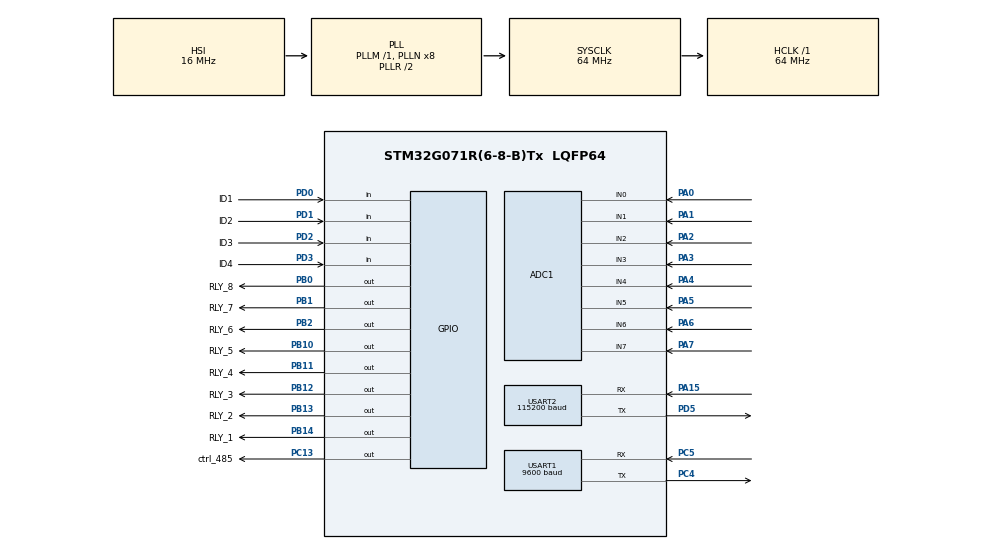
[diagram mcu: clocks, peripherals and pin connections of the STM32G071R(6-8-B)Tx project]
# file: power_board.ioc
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ADC1.Channel-0\#ChannelRegularConversion=ADC_CHANNEL_0
ADC1.Channel-1\#ChannelRegularConversion=ADC_CHANNEL_1
ADC1.Channel-2\#ChannelRegularConversion=ADC_CHANNEL_2
ADC1.Channel-3\#ChannelRegularConversion=ADC_CHANNEL_3
ADC1.Channel-4\#ChannelRegularConversion=ADC_CHANNEL_4
ADC1.Channel-5\#ChannelRegularConversion=ADC_CHANNEL_5
ADC1.Channel-6\#ChannelRegularConversion=ADC_CHANNEL_6
ADC1.Channel-7\#ChannelRegularConversion=ADC_CHANNEL_7
ADC1.ContinuousConvMode=ENABLE
ADC1.DMAContinuousRequests=ENABLE
ADC1.NbrOfConversion=8
ADC1.NbrOfConversionFlag=1
ADC1.Rank-0\#ChannelRegularConversion=1
ADC1.Rank-1\#ChannelRegularConversion=2
ADC1.Rank-2\#ChannelRegularConversion=3
ADC1.Rank-3\#ChannelRegularConversion=4
ADC1.Rank-4\#ChannelRegularConversion=5
ADC1.Rank-5\#ChannelRegularConversion=6
ADC1.Rank-6\#ChannelRegularConversion=7
ADC1.Rank-7\#ChannelRegularConversion=8
ADC1.SamplingTime-0\#ChannelRegularConversion=ADC_SAMPLINGTIME_COMMON_1
ADC1.SamplingTime-1\#ChannelRegularConversion=ADC_SAMPLINGTIME_COMMON_1
ADC1.SamplingTime-2\#ChannelRegularConversion=ADC_SAMPLINGTIME_COMMON_1
ADC1.SamplingTime-3\#ChannelRegularConversion=ADC_SAMPLINGTIME_COMMON_1
ADC1.SamplingTime-4\#ChannelRegularConversion=ADC_SAMPLINGTIME_COMMON_1
ADC1.SamplingTime-5\#ChannelRegularConversion=ADC_SAMPLINGTIME_COMMON_1
ADC1.SamplingTime-6\#ChannelRegularConversion=ADC_SAMPLINGTIME_COMMON_1
ADC1.SamplingTime-7\#ChannelRegularConversion=ADC_SAMPLINGTIME_COMMON_1
ADC1.SamplingTimeCommon1=ADC_SAMPLETIME_12CYCLES_5
ADC1.SamplingTimeCommon2=ADC_SAMPLETIME_12CYCLES_5
ADC1.SelectedChannel=ADC_CHANNEL_0|ADC_CHANNEL_1|ADC_CHANNEL_2|ADC_CHANNEL_3|ADC_CHANNEL_4|ADC_CHANNEL_5|ADC_CHANNEL_6|ADC_CHANNEL_7
ADC1.master=1
Dma.ADC1.0.Direction=DMA_PERIPH_TO_MEMORY
Dma.ADC1.0.EventEnable=DISABLE
Dma.ADC1.0.Instance=DMA1_Channel1
Dma.ADC1.0.MemDataAlignment=DMA_MDATAALIGN_HALFWORD
Dma.ADC1.0.MemInc=DMA_MINC_ENABLE
Dma.ADC1.0.Mode=DMA_CIRCULAR
Dma.ADC1.0.PeriphDataAlignment=DMA_PDATAALIGN_HALFWORD
Dma.ADC1.0.PeriphInc=DMA_PINC_DISABLE
Dma.ADC1.0.Polarity=HAL_DMAMUX_REQ_GEN_RISING
Dma.ADC1.0.Priority=DMA_PRIORITY_LOW
Dma.ADC1.0.RequestNumber=1
Dma.ADC1.0.SignalID=NONE
Dma.ADC1.0.SyncEnable=DISABLE
Dma.ADC1.0.SyncPolarity=HAL_DMAMUX_SYNC_NO_EVENT
Dma.ADC1.0.SyncRequestNumber=1
Dma.ADC1.0.SyncSignalID=NONE
Dma.Request0=ADC1
Mcu.Family=STM32G0
Mcu.Name=STM32G071R(6-8-B)Tx
Mcu.Package=LQFP64
NVIC.DMA1_Channel1_IRQn=true\:0\:0\:false\:false\:true\:false\:true\:true
NVIC.USART1_IRQn=true\:0\:0\:false\:false\:true\:true\:true\:true
PA0.Mode=IN0
PA0.Signal=ADC1_IN0
PA1.Mode=IN1
PA1.Signal=ADC1_IN1
PA13.Mode=Serial_Wire
PA13.Signal=SYS_SWDIO
PA14-BOOT0.Mode=Serial_Wire
PA14-BOOT0.Signal=SYS_SWCLK
PA15.Mode=Asynchronous
PA15.Signal=USART2_RX
PA2.Mode=IN2
PA2.Signal=ADC1_IN2
PA3.Mode=IN3
PA3.Signal=ADC1_IN3
PA4.Mode=IN4
PA4.Signal=ADC1_IN4
PA5.Mode=IN5
PA5.Signal=ADC1_IN5
PA6.Mode=IN6
PA6.Signal=ADC1_IN6
PA7.Mode=IN7
PA7.Signal=ADC1_IN7
PB0.GPIO_Label=RLY_8
PB0.Signal=GPIO_Output
PB1.GPIO_Label=RLY_7
PB1.Signal=GPIO_Output
PB10.GPIO_Label=RLY_5
PB10.Signal=GPIO_Output
PB11.GPIO_Label=RLY_4
PB11.Signal=GPIO_Output
PB12.GPIO_Label=RLY_3
PB12.Signal=GPIO_Output
PB13.GPIO_Label=RLY_2
PB13.Signal=GPIO_Output
PB14.GPIO_Label=RLY_1
PB14.Signal=GPIO_Output
PB2.GPIO_Label=RLY_6
PB2.Signal=GPIO_Output
PC13.GPIO_Label=ctrl_485
PC13.Signal=GPIO_Output
PC4.Mode=Asynchronous
PC4.Signal=USART1_TX
PC5.Mode=Asynchronous
PC5.Signal=USART1_RX
PD0.GPIO_Label=ID1
PD0.GPIO_PuPd=GPIO_PULLUP
PD0.Signal=GPIO_Input
PD1.GPIO_Label=ID2
PD1.GPIO_PuPd=GPIO_PULLUP
PD1.Signal=GPIO_Input
PD2.GPIO_Label=ID3
PD2.GPIO_PuPd=GPIO_PULLUP
PD2.Signal=GPIO_Input
PD3.GPIO_Label=ID4
PD3.GPIO_PuPd=GPIO_PULLUP
PD3.Signal=GPIO_Input
PD5.Mode=Asynchronous
PD5.Signal=USART2_TX
ProjectManager.HeapSize=0x200
ProjectManager.StackSize=0x400
ProjectManager.TargetToolchain=STM32CubeIDE
RCC.ADCFreq_Value=64000000
RCC.AHBFreq_Value=64000000
RCC.CortexFreq_Value=64000000
RCC.EXTERNAL_CLOCK_VALUE=48000
RCC.HCLKFreq_Value=64000000
RCC.HSE_VALUE=8000000
RCC.HSI_VALUE=16000000
RCC.LSE_VALUE=32768
RCC.SYSCLKFreq_VALUE=64000000
RCC.SYSCLKSource=RCC_SYSCLKSOURCE_PLLCLK
RCC.VCOOutputFreq_Value=128000000
USART1.BaudRate=9600
USART1.VirtualMode-Asynchronous=VM_ASYNC
USART2.BaudRate=115200
USART2.VirtualMode-Asynchronous=VM_ASYNC
board=custom

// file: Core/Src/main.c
/* USER CODE BEGIN Header */
/**
  ******************************************************************************
  * @file           : main.c
  * @brief          : Main program body
  ******************************************************************************
  * @attention
  *
  * Copyright (c) 2026 STMicroelectronics.
  * All rights reserved.
  *
  * This software is licensed under terms that can be found in the LICENSE file
  * in the root directory of this software component.
  * If no LICENSE file comes with this software, it is provided AS-IS.
  *
  ******************************************************************************
  */
/* USER CODE END Header */
#include "main.h"

/* USER CODE BEGIN Includes */
#include "app.h"
#include <stdio.h>
/* USER CODE END Includes */

ADC_HandleTypeDef hadc1;
DMA_HandleTypeDef hdma_adc1;

UART_HandleTypeDef huart1;
UART_HandleTypeDef huart2;

void SystemClock_Config(void);
static void MX_GPIO_Init(void);
static void MX_DMA_Init(void);
static void MX_ADC1_Init(void);
static void MX_USART1_UART_Init(void);
static void MX_USART2_UART_Init(void);

int main(void)
{

  /* MCU Configuration--------------------------------------------------------*/

  /* Reset of all peripherals, Initializes the Flash interface and the Systick. */
  HAL_Init();

  /* Configure the system clock */
  SystemClock_Config();

  /* Initialize all configured peripherals */
  MX_GPIO_Init();
  MX_DMA_Init();
  MX_ADC1_Init();
  MX_USART1_UART_Init();
  MX_USART2_UART_Init();

  /* Infinite loop */
  /* USER CODE BEGIN WHILE */
  App_Init();
  while (1)
  {

	  App_Run();
    /* USER CODE END WHILE */

  }
}

void SystemClock_Config(void)
{
  RCC_OscInitTypeDef RCC_OscInitStruct = {0};
  RCC_ClkInitTypeDef RCC_ClkInitStruct = {0};

  /** Configure the main internal regulator output voltage
  */
  HAL_PWREx_ControlVoltageScaling(PWR_REGULATOR_VOLTAGE_SCALE1);

  /** Initializes the RCC Oscillators according to the specified parameters
  * in the RCC_OscInitTypeDef structure.
  */
  RCC_OscInitStruct.OscillatorType = RCC_OSCILLATORTYPE_HSI;
  RCC_OscInitStruct.HSIState = RCC_HSI_ON;
  RCC_OscInitStruct.HSIDiv = RCC_HSI_DIV1;
  RCC_OscInitStruct.HSICalibrationValue = RCC_HSICALIBRATION_DEFAULT;
  RCC_OscInitStruct.PLL.PLLState = RCC_PLL_ON;
  RCC_OscInitStruct.PLL.PLLSource = RCC_PLLSOURCE_HSI;
  RCC_OscInitStruct.PLL.PLLM = RCC_PLLM_DIV1;
  RCC_OscInitStruct.PLL.PLLN = 8;
  RCC_OscInitStruct.PLL.PLLP = RCC_PLLP_DIV2;
  RCC_OscInitStruct.PLL.PLLQ = RCC_PLLQ_DIV2;
  RCC_OscInitStruct.PLL.PLLR = RCC_PLLR_DIV2;
  if (HAL_RCC_OscConfig(&RCC_OscInitStruct) != HAL_OK)
  {
    Error_Handler();
  }

  /** Initializes the CPU, AHB and APB buses clocks
  */
  RCC_ClkInitStruct.ClockType = RCC_CLOCKTYPE_HCLK|RCC_CLOCKTYPE_SYSCLK
                              |RCC_CLOCKTYPE_PCLK1;
  RCC_ClkInitStruct.SYSCLKSource = RCC_SYSCLKSOURCE_PLLCLK;
  RCC_ClkInitStruct.AHBCLKDivider = RCC_SYSCLK_DIV1;
  RCC_ClkInitStruct.APB1CLKDivider = RCC_HCLK_DIV1;

  if (HAL_RCC_ClockConfig(&RCC_ClkInitStruct, FLASH_LATENCY_2) != HAL_OK)
  {
    Error_Handler();
  }
}

static void MX_ADC1_Init(void)
{

  ADC_ChannelConfTypeDef sConfig = {0};

  /** Configure the global features of the ADC (Clock, Resolution, Data Alignment and number of conversion)
  */
  hadc1.Instance = ADC1;
  hadc1.Init.ClockPrescaler = ADC_CLOCK_SYNC_PCLK_DIV2;
  hadc1.Init.Resolution = ADC_RESOLUTION_12B;
  hadc1.Init.DataAlign = ADC_DATAALIGN_RIGHT;
  hadc1.Init.ScanConvMode = ADC_SCAN_ENABLE;
  hadc1.Init.EOCSelection = ADC_EOC_SINGLE_CONV;
  hadc1.Init.LowPowerAutoWait = DISABLE;
  hadc1.Init.LowPowerAutoPowerOff = DISABLE;
  hadc1.Init.ContinuousConvMode = ENABLE;
  hadc1.Init.NbrOfConversion = 8;
  hadc1.Init.ExternalTrigConv = ADC_SOFTWARE_START;
  hadc1.Init.ExternalTrigConvEdge = ADC_EXTERNALTRIGCONVEDGE_NONE;
  hadc1.Init.DMAContinuousRequests = ENABLE;
  hadc1.Init.Overrun = ADC_OVR_DATA_PRESERVED;
  hadc1.Init.SamplingTimeCommon1 = ADC_SAMPLETIME_12CYCLES_5;
  hadc1.Init.SamplingTimeCommon2 = ADC_SAMPLETIME_12CYCLES_5;
  hadc1.Init.OversamplingMode = DISABLE;
  hadc1.Init.TriggerFrequencyMode = ADC_TRIGGER_FREQ_HIGH;
  if (HAL_ADC_Init(&hadc1) != HAL_OK)
  {
    Error_Handler();
  }

  /** Configure Regular Channel
  */
  sConfig.Channel = ADC_CHANNEL_0;
  sConfig.Rank = ADC_REGULAR_RANK_1;
  sConfig.SamplingTime = ADC_SAMPLINGTIME_COMMON_1;
  if (HAL_ADC_ConfigChannel(&hadc1, &sConfig) != HAL_OK)
  {
    Error_Handler();
  }

  /** Configure Regular Channel
  */
  sConfig.Channel = ADC_CHANNEL_1;
  sConfig.Rank = ADC_REGULAR_RANK_2;
  if (HAL_ADC_ConfigChannel(&hadc1, &sConfig) != HAL_OK)
  {
    Error_Handler();
  }

  /** Configure Regular Channel
  */
  sConfig.Channel = ADC_CHANNEL_2;
  sConfig.Rank = ADC_REGULAR_RANK_3;
  if (HAL_ADC_ConfigChannel(&hadc1, &sConfig) != HAL_OK)
  {
    Error_Handler();
  }

  /** Configure Regular Channel
  */
  sConfig.Channel = ADC_CHANNEL_3;
  sConfig.Rank = ADC_REGULAR_RANK_4;
  if (HAL_ADC_ConfigChannel(&hadc1, &sConfig) != HAL_OK)
  {
    Error_Handler();
  }

  /** Configure Regular Channel
  */
  sConfig.Channel = ADC_CHANNEL_4;
  sConfig.Rank = ADC_REGULAR_RANK_5;
  if (HAL_ADC_ConfigChannel(&hadc1, &sConfig) != HAL_OK)
  {
    Error_Handler();
  }

  /** Configure Regular Channel
  */
  sConfig.Channel = ADC_CHANNEL_5;
  sConfig.Rank = ADC_REGULAR_RANK_6;
  if (HAL_ADC_ConfigChannel(&hadc1, &sConfig) != HAL_OK)
  {
    Error_Handler();
  }

  /** Configure Regular Channel
  */
  sConfig.Channel = ADC_CHANNEL_6;
  sConfig.Rank = ADC_REGULAR_RANK_7;
  if (HAL_ADC_ConfigChannel(&hadc1, &sConfig) != HAL_OK)
  {
    Error_Handler();
  }

  /** Configure Regular Channel
  */
  sConfig.Channel = ADC_CHANNEL_7;
  sConfig.Rank = ADC_REGULAR_RANK_8;
  if (HAL_ADC_ConfigChannel(&hadc1, &sConfig) != HAL_OK)
  {
    Error_Handler();
  }

}

static void MX_USART1_UART_Init(void)
{

  huart1.Instance = USART1;
  huart1.Init.BaudRate = 9600;
  huart1.Init.WordLength = UART_WORDLENGTH_8B;
  huart1.Init.StopBits = UART_STOPBITS_1;
  huart1.Init.Parity = UART_PARITY_NONE;
  huart1.Init.Mode = UART_MODE_TX_RX;
  huart1.Init.HwFlowCtl = UART_HWCONTROL_NONE;
  huart1.Init.OverSampling = UART_OVERSAMPLING_16;
  huart1.Init.OneBitSampling = UART_ONE_BIT_SAMPLE_DISABLE;
  huart1.Init.ClockPrescaler = UART_PRESCALER_DIV1;
  huart1.AdvancedInit.AdvFeatureInit = UART_ADVFEATURE_NO_INIT;
  if (HAL_UART_Init(&huart1) != HAL_OK)
  {
    Error_Handler();
  }
  if (HAL_UARTEx_SetTxFifoThreshold(&huart1, UART_TXFIFO_THRESHOLD_1_8) != HAL_OK)
  {
    Error_Handler();
  }
  if (HAL_UARTEx_SetRxFifoThreshold(&huart1, UART_RXFIFO_THRESHOLD_1_8) != HAL_OK)
  {
    Error_Handler();
  }
  if (HAL_UARTEx_DisableFifoMode(&huart1) != HAL_OK)
  {
    Error_Handler();
  }

}

static void MX_USART2_UART_Init(void)
{

  huart2.Instance = USART2;
  huart2.Init.BaudRate = 115200;
  huart2.Init.WordLength = UART_WORDLENGTH_8B;
  huart2.Init.StopBits = UART_STOPBITS_1;
  huart2.Init.Parity = UART_PARITY_NONE;
  huart2.Init.Mode = UART_MODE_TX_RX;
  huart2.Init.HwFlowCtl = UART_HWCONTROL_NONE;
  huart2.Init.OverSampling = UART_OVERSAMPLING_16;
  huart2.Init.OneBitSampling = UART_ONE_BIT_SAMPLE_DISABLE;
  huart2.Init.ClockPrescaler = UART_PRESCALER_DIV1;
  huart2.AdvancedInit.AdvFeatureInit = UART_ADVFEATURE_NO_INIT;
  if (HAL_UART_Init(&huart2) != HAL_OK)
  {
    Error_Handler();
  }
  if (HAL_UARTEx_SetTxFifoThreshold(&huart2, UART_TXFIFO_THRESHOLD_1_8) != HAL_OK)
  {
    Error_Handler();
  }
  if (HAL_UARTEx_SetRxFifoThreshold(&huart2, UART_RXFIFO_THRESHOLD_1_8) != HAL_OK)
  {
    Error_Handler();
  }
  if (HAL_UARTEx_DisableFifoMode(&huart2) != HAL_OK)
  {
    Error_Handler();
  }

}

static void MX_DMA_Init(void)
{

  /* DMA controller clock enable */
  __HAL_RCC_DMA1_CLK_ENABLE();

  /* DMA interrupt init */
  /* DMA1_Channel1_IRQn interrupt configuration */
  HAL_NVIC_SetPriority(DMA1_Channel1_IRQn, 0, 0);
  HAL_NVIC_EnableIRQ(DMA1_Channel1_IRQn);

}

static void MX_GPIO_Init(void)
{
  GPIO_InitTypeDef GPIO_InitStruct = {0};

  /* GPIO Ports Clock Enable */
  __HAL_RCC_GPIOC_CLK_ENABLE();
  __HAL_RCC_GPIOA_CLK_ENABLE();
  __HAL_RCC_GPIOB_CLK_ENABLE();
  __HAL_RCC_GPIOD_CLK_ENABLE();

  /*Configure GPIO pin Output Level */
  HAL_GPIO_WritePin(ctrl_485_GPIO_Port, ctrl_485_Pin, GPIO_PIN_RESET);

  /*Configure GPIO pin Output Level */
  HAL_GPIO_WritePin(GPIOB, RLY_8_Pin|RLY_7_Pin|RLY_6_Pin|RLY_5_Pin
                          |RLY_4_Pin|RLY_3_Pin|RLY_2_Pin|RLY_1_Pin, GPIO_PIN_RESET);

  /*Configure GPIO pin : ctrl_485_Pin */
  GPIO_InitStruct.Pin = ctrl_485_Pin;
  GPIO_InitStruct.Mode = GPIO_MODE_OUTPUT_PP;
  GPIO_InitStruct.Pull = GPIO_NOPULL;
  GPIO_InitStruct.Speed = GPIO_SPEED_FREQ_LOW;
  HAL_GPIO_Init(ctrl_485_GPIO_Port, &GPIO_InitStruct);

  /*Configure GPIO pins : RLY_8_Pin RLY_7_Pin RLY_6_Pin RLY_5_Pin
                           RLY_4_Pin RLY_3_Pin RLY_2_Pin RLY_1_Pin */
  GPIO_InitStruct.Pin = RLY_8_Pin|RLY_7_Pin|RLY_6_Pin|RLY_5_Pin
                          |RLY_4_Pin|RLY_3_Pin|RLY_2_Pin|RLY_1_Pin;
  GPIO_InitStruct.Mode = GPIO_MODE_OUTPUT_PP;
  GPIO_InitStruct.Pull = GPIO_NOPULL;
  GPIO_InitStruct.Speed = GPIO_SPEED_FREQ_LOW;
  HAL_GPIO_Init(GPIOB, &GPIO_InitStruct);

  /*Configure GPIO pins : ID1_Pin ID2_Pin ID3_Pin ID4_Pin */
  GPIO_InitStruct.Pin = ID1_Pin|ID2_Pin|ID3_Pin|ID4_Pin;
  GPIO_InitStruct.Mode = GPIO_MODE_INPUT;
  GPIO_InitStruct.Pull = GPIO_PULLUP;
  HAL_GPIO_Init(GPIOD, &GPIO_InitStruct);

}

void Error_Handler(void)
{
  __disable_irq();
  while (1)
  {
  }
}
